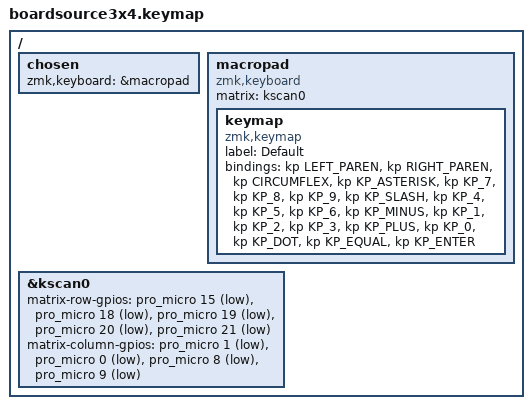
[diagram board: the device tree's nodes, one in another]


#include <dt-bindings/zmk/keys.h>
#include <dt-bindings/zmk/bt.h>
#include <dt-bindings/zmk/ext_power.h>

/ {
    chosen {
        zmk,keyboard = &macropad;
    };

    macropad {
        compatible = "zmk,keyboard";
        
        matrix = <&kscan0>;

        keymap {
            compatible = "zmk,keymap";
            label = "Default";

            bindings = <
                &kp LEFT_PAREN   &kp RIGHT_PAREN   &kp CIRCUMFLEX   &kp KP_ASTERISK
                &kp KP_7         &kp KP_8         &kp KP_9         &kp KP_SLASH
                &kp KP_4         &kp KP_5         &kp KP_6         &kp KP_MINUS
                &kp KP_1         &kp KP_2         &kp KP_3         &kp KP_PLUS
                &kp KP_0         &kp KP_DOT       &kp KP_EQUAL     &kp KP_ENTER
            >;
        };
    };

    &kscan0 {
        matrix-row-gpios = <&pro_micro 15 GPIO_ACTIVE_LOW>,
                           <&pro_micro 18 GPIO_ACTIVE_LOW>,
                           <&pro_micro 19 GPIO_ACTIVE_LOW>,
                           <&pro_micro 20 GPIO_ACTIVE_LOW>,
                           <&pro_micro 21 GPIO_ACTIVE_LOW>;
        matrix-column-gpios = <&pro_micro 1 GPIO_ACTIVE_LOW>,
                              <&pro_micro 0 GPIO_ACTIVE_LOW>,
                              <&pro_micro 8 GPIO_ACTIVE_LOW>,
                              <&pro_micro 9 GPIO_ACTIVE_LOW>;
    };
};
